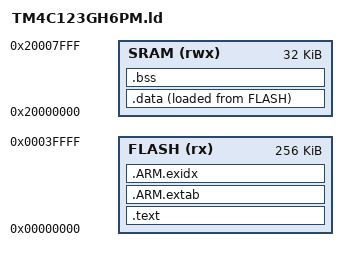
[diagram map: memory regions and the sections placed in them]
/* Linker script for TM4C123GH6PM */

MEMORY
{
    FLASH (rx) : ORIGIN = 0x00000000, LENGTH = 0x00040000
    SRAM (rwx) : ORIGIN = 0x20000000, LENGTH = 0x00008000
}

_stack_size = 4K;

SECTIONS
{
    .text :
    {
        _text = .;
        KEEP(*(.isr_vector))
        *(.text*)
        *(.rodata*)
        _etext = .;
    } > FLASH

    .data :
    {
        _data = .;
        *(vtable)
        *(.data*)
        _edata = .;
    } > SRAM AT > FLASH

    .ARM.extab   : { *(.ARM.extab* .gnu.linkonce.armextab.*) } > FLASH
    __exidx_start = .;
    .ARM.exidx   : { *(.ARM.exidx* .gnu.linkonce.armexidx.*) } > FLASH
    __exidx_end = .;

    .bss :
    {
        _bss = .;
        *(.bss*)
        *(COMMON)
        _ebss = .;
    } > SRAM
    _heap_bottom = ALIGN(8);
    _heap_top = ORIGIN(SRAM) + LENGTH(SRAM) - _stack_size;
    _stack_bottom = ALIGN(8);
    _stack_top = ORIGIN(SRAM) + LENGTH(SRAM);

}
